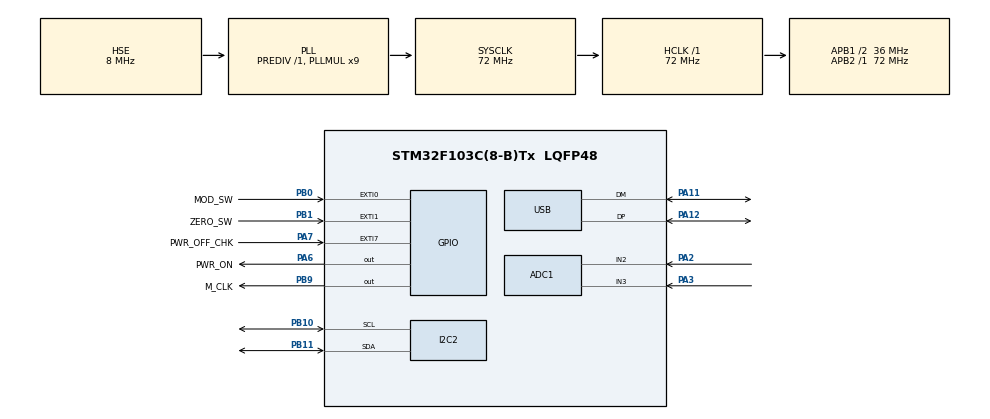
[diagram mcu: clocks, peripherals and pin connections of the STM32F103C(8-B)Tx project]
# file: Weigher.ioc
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ADC1.Channel-0\#ChannelRegularConversion=ADC_CHANNEL_2
ADC1.Channel-1\#ChannelRegularConversion=ADC_CHANNEL_3
ADC1.DiscontinuousConvMode=ENABLE
ADC1.NbrOfConversion=2
ADC1.NbrOfConversionFlag=1
ADC1.Rank-0\#ChannelRegularConversion=1
ADC1.Rank-1\#ChannelRegularConversion=2
ADC1.SamplingTime-0\#ChannelRegularConversion=ADC_SAMPLETIME_28CYCLES_5
ADC1.SamplingTime-1\#ChannelRegularConversion=ADC_SAMPLETIME_28CYCLES_5
ADC1.master=1
I2C2.I2C_Mode=I2C_Fast
Mcu.Family=STM32F1
Mcu.Name=STM32F103C(8-B)Tx
Mcu.Package=LQFP48
NVIC.EXTI0_IRQn=true\:2\:0\:true\:false\:true\:true\:true\:true
NVIC.EXTI1_IRQn=true\:2\:0\:true\:false\:true\:true\:true\:true
NVIC.EXTI9_5_IRQn=true\:2\:0\:true\:false\:true\:true\:true\:true
NVIC.PriorityGroup=NVIC_PRIORITYGROUP_4
NVIC.TIM1_BRK_IRQn=true\:0\:0\:false\:false\:true\:true\:true\:true
NVIC.TIM1_UP_IRQn=true\:0\:0\:false\:false\:true\:true\:true\:true
NVIC.USB_LP_CAN1_RX0_IRQn=true\:0\:0\:false\:false\:true\:false\:true\:true
PA11.Mode=Device
PA11.Signal=USB_DM
PA12.Mode=Device
PA12.Signal=USB_DP
PA2.Signal=ADCx_IN2
PA3.Signal=ADCx_IN3
PA6.GPIO_Label=PWR_ON
PA6.GPIO_PuPd=GPIO_NOPULL
PA6.Signal=GPIO_Output
PA7.GPIO_Label=PWR_OFF_CHK
PA7.GPIO_ModeDefaultEXTI=GPIO_MODE_IT_FALLING
PA7.GPIO_PuPd=GPIO_PULLUP
PA7.Signal=GPXTI7
PB0.GPIO_Label=MOD_SW
PB0.GPIO_ModeDefaultEXTI=GPIO_MODE_IT_FALLING
PB0.GPIO_PuPd=GPIO_PULLUP
PB0.Signal=GPXTI0
PB1.GPIO_Label=ZERO_SW
PB1.GPIO_ModeDefaultEXTI=GPIO_MODE_IT_FALLING
PB1.GPIO_PuPd=GPIO_PULLUP
PB1.Signal=GPXTI1
PB10.Mode=I2C
PB10.Signal=I2C2_SCL
PB11.Mode=I2C
PB11.Signal=I2C2_SDA
PB9.GPIO_Label=M_CLK
PB9.Signal=GPIO_Output
PD0-OSC_IN.Mode=HSE-External-Oscillator
PD0-OSC_IN.Signal=RCC_OSC_IN
PD1-OSC_OUT.Mode=HSE-External-Oscillator
PD1-OSC_OUT.Signal=RCC_OSC_OUT
ProjectManager.HeapSize=0x600
ProjectManager.StackSize=0x800
ProjectManager.TargetToolchain=MDK-ARM V5.32
RCC.ADCPresc=RCC_ADCPCLK2_DIV6
RCC.AHBFreq_Value=72000000
RCC.APB1CLKDivider=RCC_HCLK_DIV2
RCC.APB1Freq_Value=36000000
RCC.APB1TimFreq_Value=72000000
RCC.APB2Freq_Value=72000000
RCC.APB2TimFreq_Value=72000000
RCC.HCLKFreq_Value=72000000
RCC.PLLMUL=RCC_PLL_MUL9
RCC.PLLSourceVirtual=RCC_PLLSOURCE_HSE
RCC.SYSCLKFreq_VALUE=72000000
RCC.SYSCLKSource=RCC_SYSCLKSOURCE_PLLCLK
RCC.USBFreq_Value=48000000
RCC.USBPrescaler=RCC_USBCLKSOURCE_PLL_DIV1_5
SH.ADCx_IN2.0=ADC1_IN2,IN2
SH.ADCx_IN3.0=ADC1_IN3,IN3
TIM1.Period=10000-1
TIM1.Prescaler=72-1
TIM2.Period=100-1
TIM2.Prescaler=3600-1
TIM3.Period=4000-1
TIM3.Prescaler=360-1
USB_DEVICE.CLASS_NAME_FS=CDC
USB_DEVICE.VID=8855
USB_DEVICE.VirtualMode=Cdc
USB_DEVICE.VirtualModeFS=Cdc_FS
VP_SYS_VS_ND.Mode=No_Debug
VP_TIM1_VS_ClockSourceINT.Mode=Internal
VP_TIM2_VS_ClockSourceINT.Mode=Internal
VP_TIM3_VS_ClockSourceINT.Mode=Internal
VP_USB_DEVICE_VS_USB_DEVICE_CDC_FS.Mode=CDC_FS
board=custom

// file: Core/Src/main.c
/* USER CODE BEGIN Header */
/**
  ******************************************************************************
  * @file           : main.c
  * @brief          : Main program body
  ******************************************************************************
  * @attention
  *
  * Copyright (c) 2024 STMicroelectronics.
  * All rights reserved.
  *
  * This software is licensed under terms that can be found in the LICENSE file
  * in the root directory of this software component.
  * If no LICENSE file comes with this software, it is provided AS-IS.
  *
  ******************************************************************************
  */
/* USER CODE END Header */
#include "main.h"
#include "adc.h"
#include "i2c.h"
#include "tim.h"
#include "usb_device.h"
#include "gpio.h"

/* USER CODE BEGIN Includes */
#include "system.h"
#include "screen.h"

/* USER CODE END Includes */

void SystemClock_Config(void);

int main(void)
{

  /* MCU Configuration--------------------------------------------------------*/

  /* Reset of all peripherals, Initializes the Flash interface and the Systick. */
  HAL_Init();

  /* Configure the system clock */
  SystemClock_Config();

  /* USER CODE BEGIN SysInit */
//	LL_usb_reload();
  /* USER CODE END SysInit */

  /* Initialize all configured peripherals */
  MX_GPIO_Init();
  MX_TIM1_Init();
  MX_TIM2_Init();
  MX_TIM3_Init();
//  MX_USB_DEVICE_Init();
  MX_ADC1_Init();
  MX_I2C2_Init();
  /* USER CODE BEGIN 2 */
	system_Init();
	LL_usb_reload();
  MX_USB_DEVICE_Init();
  /* USER CODE END 2 */

  /* Infinite loop */
  /* USER CODE BEGIN WHILE */
  while (1)
  {
		system_GO();
//		u8g2_test(&u8g2);
//		CS1237ReadInterlTemp();
//		HAL_Delay(100);
//		Read_CS1237();
    /* USER CODE END WHILE */

  }
}

void SystemClock_Config(void)
{
  RCC_OscInitTypeDef RCC_OscInitStruct = {0};
  RCC_ClkInitTypeDef RCC_ClkInitStruct = {0};
  RCC_PeriphCLKInitTypeDef PeriphClkInit = {0};

  /** Initializes the RCC Oscillators according to the specified parameters
  * in the RCC_OscInitTypeDef structure.
  */
  RCC_OscInitStruct.OscillatorType = RCC_OSCILLATORTYPE_HSE;
  RCC_OscInitStruct.HSEState = RCC_HSE_ON;
  RCC_OscInitStruct.HSEPredivValue = RCC_HSE_PREDIV_DIV1;
  RCC_OscInitStruct.HSIState = RCC_HSI_ON;
  RCC_OscInitStruct.PLL.PLLState = RCC_PLL_ON;
  RCC_OscInitStruct.PLL.PLLSource = RCC_PLLSOURCE_HSE;
  RCC_OscInitStruct.PLL.PLLMUL = RCC_PLL_MUL9;
  if (HAL_RCC_OscConfig(&RCC_OscInitStruct) != HAL_OK)
  {
    Error_Handler();
  }

  /** Initializes the CPU, AHB and APB buses clocks
  */
  RCC_ClkInitStruct.ClockType = RCC_CLOCKTYPE_HCLK|RCC_CLOCKTYPE_SYSCLK
                              |RCC_CLOCKTYPE_PCLK1|RCC_CLOCKTYPE_PCLK2;
  RCC_ClkInitStruct.SYSCLKSource = RCC_SYSCLKSOURCE_PLLCLK;
  RCC_ClkInitStruct.AHBCLKDivider = RCC_SYSCLK_DIV1;
  RCC_ClkInitStruct.APB1CLKDivider = RCC_HCLK_DIV2;
  RCC_ClkInitStruct.APB2CLKDivider = RCC_HCLK_DIV1;

  if (HAL_RCC_ClockConfig(&RCC_ClkInitStruct, FLASH_LATENCY_2) != HAL_OK)
  {
    Error_Handler();
  }
  PeriphClkInit.PeriphClockSelection = RCC_PERIPHCLK_ADC|RCC_PERIPHCLK_USB;
  PeriphClkInit.AdcClockSelection = RCC_ADCPCLK2_DIV6;
  PeriphClkInit.UsbClockSelection = RCC_USBCLKSOURCE_PLL_DIV1_5;
  if (HAL_RCCEx_PeriphCLKConfig(&PeriphClkInit) != HAL_OK)
  {
    Error_Handler();
  }
}

void Error_Handler(void)
{
  __disable_irq();
  while (1)
  {
  }
}
